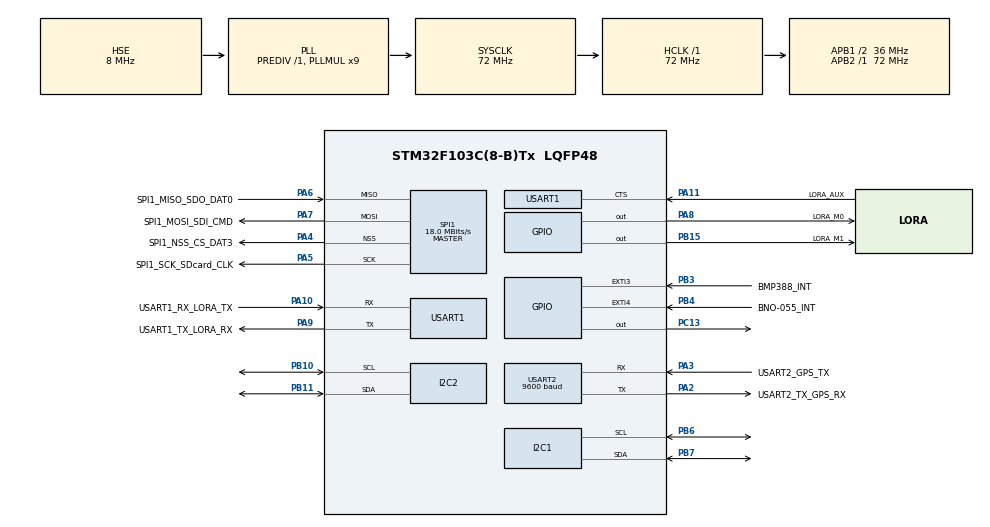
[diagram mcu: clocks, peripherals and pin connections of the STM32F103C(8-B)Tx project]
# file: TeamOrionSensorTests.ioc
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Dma.I2C1_RX.0.Direction=DMA_PERIPH_TO_MEMORY
Dma.I2C1_RX.0.Instance=DMA1_Channel7
Dma.I2C1_RX.0.MemDataAlignment=DMA_MDATAALIGN_BYTE
Dma.I2C1_RX.0.MemInc=DMA_MINC_ENABLE
Dma.I2C1_RX.0.Mode=DMA_NORMAL
Dma.I2C1_RX.0.PeriphDataAlignment=DMA_PDATAALIGN_BYTE
Dma.I2C1_RX.0.PeriphInc=DMA_PINC_DISABLE
Dma.I2C1_RX.0.Priority=DMA_PRIORITY_LOW
Dma.I2C1_TX.1.Direction=DMA_MEMORY_TO_PERIPH
Dma.I2C1_TX.1.Instance=DMA1_Channel6
Dma.I2C1_TX.1.MemDataAlignment=DMA_MDATAALIGN_BYTE
Dma.I2C1_TX.1.MemInc=DMA_MINC_ENABLE
Dma.I2C1_TX.1.Mode=DMA_NORMAL
Dma.I2C1_TX.1.PeriphDataAlignment=DMA_PDATAALIGN_BYTE
Dma.I2C1_TX.1.PeriphInc=DMA_PINC_DISABLE
Dma.I2C1_TX.1.Priority=DMA_PRIORITY_LOW
Dma.Request0=I2C1_RX
Dma.Request1=I2C1_TX
Dma.Request2=USART1_RX
Dma.Request3=USART1_TX
Dma.Request4=SPI1_RX
Dma.Request5=SPI1_TX
Dma.SPI1_RX.4.Direction=DMA_PERIPH_TO_MEMORY
Dma.SPI1_RX.4.Instance=DMA1_Channel2
Dma.SPI1_RX.4.MemDataAlignment=DMA_MDATAALIGN_BYTE
Dma.SPI1_RX.4.MemInc=DMA_MINC_ENABLE
Dma.SPI1_RX.4.Mode=DMA_NORMAL
Dma.SPI1_RX.4.PeriphDataAlignment=DMA_PDATAALIGN_BYTE
Dma.SPI1_RX.4.PeriphInc=DMA_PINC_DISABLE
Dma.SPI1_RX.4.Priority=DMA_PRIORITY_LOW
Dma.SPI1_TX.5.Direction=DMA_MEMORY_TO_PERIPH
Dma.SPI1_TX.5.Instance=DMA1_Channel3
Dma.SPI1_TX.5.MemDataAlignment=DMA_MDATAALIGN_BYTE
Dma.SPI1_TX.5.MemInc=DMA_MINC_ENABLE
Dma.SPI1_TX.5.Mode=DMA_NORMAL
Dma.SPI1_TX.5.PeriphDataAlignment=DMA_PDATAALIGN_BYTE
Dma.SPI1_TX.5.PeriphInc=DMA_PINC_DISABLE
Dma.SPI1_TX.5.Priority=DMA_PRIORITY_LOW
Dma.USART1_RX.2.Direction=DMA_PERIPH_TO_MEMORY
Dma.USART1_RX.2.Instance=DMA1_Channel5
Dma.USART1_RX.2.MemDataAlignment=DMA_MDATAALIGN_BYTE
Dma.USART1_RX.2.MemInc=DMA_MINC_ENABLE
Dma.USART1_RX.2.Mode=DMA_NORMAL
Dma.USART1_RX.2.PeriphDataAlignment=DMA_PDATAALIGN_BYTE
Dma.USART1_RX.2.PeriphInc=DMA_PINC_DISABLE
Dma.USART1_RX.2.Priority=DMA_PRIORITY_LOW
Dma.USART1_TX.3.Direction=DMA_MEMORY_TO_PERIPH
Dma.USART1_TX.3.Instance=DMA1_Channel4
Dma.USART1_TX.3.MemDataAlignment=DMA_MDATAALIGN_BYTE
Dma.USART1_TX.3.MemInc=DMA_MINC_ENABLE
Dma.USART1_TX.3.Mode=DMA_NORMAL
Dma.USART1_TX.3.PeriphDataAlignment=DMA_PDATAALIGN_BYTE
Dma.USART1_TX.3.PeriphInc=DMA_PINC_DISABLE
Dma.USART1_TX.3.Priority=DMA_PRIORITY_LOW
Mcu.Family=STM32F1
Mcu.Name=STM32F103C(8-B)Tx
Mcu.Package=LQFP48
NVIC.DMA1_Channel2_IRQn=true\:0\:0\:false\:false\:true\:false\:true\:true
NVIC.DMA1_Channel3_IRQn=true\:0\:0\:false\:false\:true\:false\:true\:true
NVIC.DMA1_Channel4_IRQn=true\:0\:0\:false\:false\:true\:false\:true\:true
NVIC.DMA1_Channel5_IRQn=true\:0\:0\:false\:false\:true\:false\:true\:true
NVIC.DMA1_Channel6_IRQn=true\:0\:0\:false\:false\:true\:false\:true\:true
NVIC.DMA1_Channel7_IRQn=true\:0\:0\:false\:false\:true\:false\:true\:true
NVIC.PriorityGroup=NVIC_PRIORITYGROUP_4
NVIC.USART2_IRQn=true\:0\:0\:false\:false\:true\:true\:true\:true
PA10.GPIO_Label=USART1_RX_LORA_TX
PA10.Mode=Asynchronous
PA10.Signal=USART1_RX
PA11.GPIO_Label=LORA_AUX
PA11.Mode=CTS_Only
PA11.Signal=USART1_CTS
PA13.Mode=Serial_Wire
PA13.Signal=SYS_JTMS-SWDIO
PA14.Mode=Serial_Wire
PA14.Signal=SYS_JTCK-SWCLK
PA2.GPIO_Label=USART2_TX_GPS_RX
PA2.Mode=Asynchronous
PA2.Signal=USART2_TX
PA3.GPIO_Label=USART2_GPS_TX
PA3.Mode=Asynchronous
PA3.Signal=USART2_RX
PA4.GPIO_Label=SPI1_NSS_CS_DAT3
PA4.Mode=NSS_Signal_Hard_Output
PA4.Signal=SPI1_NSS
PA5.GPIO_Label=SPI1_SCK_SDcard_CLK
PA5.Mode=Full_Duplex_Master
PA5.Signal=SPI1_SCK
PA6.GPIO_Label=SPI1_MISO_SDO_DAT0
PA6.Mode=Full_Duplex_Master
PA6.Signal=SPI1_MISO
PA7.GPIO_Label=SPI1_MOSI_SDI_CMD
PA7.Mode=Full_Duplex_Master
PA7.Signal=SPI1_MOSI
PA8.GPIO_Label=LORA_M0
PA8.Signal=GPIO_Output
PA9.GPIO_Label=USART1_TX_LORA_RX
PA9.Mode=Asynchronous
PA9.Signal=USART1_TX
PB10.Mode=I2C
PB10.Signal=I2C2_SCL
PB11.Mode=I2C
PB11.Signal=I2C2_SDA
PB15.GPIO_Label=LORA_M1
PB15.Signal=GPIO_Output
PB3.GPIO_Label=BMP388_INT
PB3.Signal=GPXTI3
PB4.GPIO_Label=BNO-055_INT
PB4.Signal=GPXTI4
PB6.Mode=I2C
PB6.Signal=I2C1_SCL
PB7.Mode=I2C
PB7.Signal=I2C1_SDA
PC13-TAMPER-RTC.GPIO_ModeDefaultOutputPP=GPIO_MODE_OUTPUT_PP
PC13-TAMPER-RTC.GPIO_Speed=GPIO_SPEED_FREQ_HIGH
PC13-TAMPER-RTC.Signal=GPIO_Output
PD0-OSC_IN.Mode=HSE-External-Oscillator
PD0-OSC_IN.Signal=RCC_OSC_IN
PD1-OSC_OUT.Mode=HSE-External-Oscillator
PD1-OSC_OUT.Signal=RCC_OSC_OUT
ProjectManager.HeapSize=0x200
ProjectManager.StackSize=0x400
ProjectManager.TargetToolchain=MDK-ARM V5.32
RCC.AHBFreq_Value=72000000
RCC.APB1CLKDivider=RCC_HCLK_DIV2
RCC.APB1Freq_Value=36000000
RCC.APB1TimFreq_Value=72000000
RCC.APB2Freq_Value=72000000
RCC.APB2TimFreq_Value=72000000
RCC.HCLKFreq_Value=72000000
RCC.PLLMUL=RCC_PLL_MUL9
RCC.PLLSourceVirtual=RCC_PLLSOURCE_HSE
RCC.SYSCLKFreq_VALUE=72000000
RCC.SYSCLKSource=RCC_SYSCLKSOURCE_PLLCLK
RCC.USBFreq_Value=72000000
SPI1.BaudRatePrescaler=SPI_BAUDRATEPRESCALER_4
SPI1.CLKPhase=SPI_PHASE_1EDGE
SPI1.CalculateBaudRate=18.0 MBits/s
SPI1.DataSize=SPI_DATASIZE_8BIT
SPI1.Direction=SPI_DIRECTION_2LINES
SPI1.Mode=SPI_MODE_MASTER
SPI1.VirtualNSS=VM_NSSHARD
SPI1.VirtualType=VM_MASTER
USART1.VirtualMode=VM_ASYNC
USART2.BaudRate=9600
USART2.VirtualMode=VM_ASYNC
board=custom

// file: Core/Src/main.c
/* USER CODE BEGIN Header */
/**
  ******************************************************************************
  * @file           : main.c
  * @brief          : Main program body
  ******************************************************************************
  * @attention
  *
  * Copyright (c) 2023 STMicroelectronics.
  * All rights reserved.
  *
  * This software is licensed under terms that can be found in the LICENSE file
  * in the root directory of this software component.
  * If no LICENSE file comes with this software, it is provided AS-IS.
  *
  ******************************************************************************
  */
/* USER CODE END Header */
#include "main.h"
#include "dma.h"
#include "i2c.h"
#include "spi.h"
#include "usart.h"
#include "gpio.h"

/* USER CODE BEGIN Includes */
#include "bno055_stm32.h"
#include "_BMP388.h"
#include "gps.h"
/* USER CODE END Includes */

/* USER CODE BEGIN PV */
//uint8_t x = 0;
//uint8_t y = 0;
//volatile double pressure = 0.0;
//volatile double temperature = 0.0;
//volatile double altitude = 0.0;
calibINTCoefficents calibINT;
//bno055_vector_t euler;
//bno055_vector_t quaternion;

float gpsAltitude;
float Latitude;
float Longitude;

GPS_t GPS;

/* USER CODE END PV */

void SystemClock_Config(void);

int main(void)
{

  /* MCU Configuration--------------------------------------------------------*/

  /* Reset of all peripherals, Initializes the Flash interface and the Systick. */
  HAL_Init();

  /* Configure the system clock */
  SystemClock_Config();

  /* Initialize all configured peripherals */
  MX_GPIO_Init();
  MX_DMA_Init();
  MX_I2C1_Init();
  MX_USART1_UART_Init();
  MX_SPI1_Init();
  MX_USART2_UART_Init();
  MX_I2C2_Init();
  /* USER CODE BEGIN 2 */

  GPS_Init();//GPS START COMMAND

//  bno055_setup();
//  bno055_setOperationMode(BNO055_OPERATION_MODE_NDOF);
//  x = BMP388_TestSensor();
//  y = BMP388_ReadID();
//  //															Pressure		Temperature
//  x = begin(NORMAL_MODE, IIR_FILTER_OFF, TIME_STANDBY_5MS, OVERSAMPLING_SKIP, OVERSAMPLING_SKIP);
//  readCoef();
  /* USER CODE END 2 */

  /* Infinite loop */
  while (1)
  {

    /* USER CODE BEGIN 3 */
//	euler = bno055_getVector(BNO055_VECTOR_EULER);
//	//printf("Heading: %.2f Roll: %.2f Pitch: %.2f\r\n", euler.x, euler.y, euler.z);
//	quaternion = bno055_getVector(BNO055_VECTOR_QUATERNION);
//	//printf("W: %.2f X: %.2f Y: %.2f Z: %.2f\r\n", quaternion.w, quaternion.x, quaternion.y, quaternion.z);
//	//HAL_Delay(10);
//	y = getBMP_Data(&temperature, &pressure, &altitude);

	  HAL_GPIO_TogglePin(GPIOC,13);
 	  gpsAltitude = GPS.msl_altitude;
	  Latitude = GPS.dec_latitude;
	  Longitude = GPS.dec_longitude;
	  HAL_GPIO_TogglePin(GPIOC, 13);

  }
  /* USER CODE END 3 */
}

void SystemClock_Config(void)
{
  RCC_OscInitTypeDef RCC_OscInitStruct = {0};
  RCC_ClkInitTypeDef RCC_ClkInitStruct = {0};

  /** Initializes the RCC Oscillators according to the specified parameters
  * in the RCC_OscInitTypeDef structure.
  */
  RCC_OscInitStruct.OscillatorType = RCC_OSCILLATORTYPE_HSE;
  RCC_OscInitStruct.HSEState = RCC_HSE_ON;
  RCC_OscInitStruct.HSEPredivValue = RCC_HSE_PREDIV_DIV1;
  RCC_OscInitStruct.HSIState = RCC_HSI_ON;
  RCC_OscInitStruct.PLL.PLLState = RCC_PLL_ON;
  RCC_OscInitStruct.PLL.PLLSource = RCC_PLLSOURCE_HSE;
  RCC_OscInitStruct.PLL.PLLMUL = RCC_PLL_MUL9;
  if (HAL_RCC_OscConfig(&RCC_OscInitStruct) != HAL_OK)
  {
    Error_Handler();
  }

  /** Initializes the CPU, AHB and APB buses clocks
  */
  RCC_ClkInitStruct.ClockType = RCC_CLOCKTYPE_HCLK|RCC_CLOCKTYPE_SYSCLK
                              |RCC_CLOCKTYPE_PCLK1|RCC_CLOCKTYPE_PCLK2;
  RCC_ClkInitStruct.SYSCLKSource = RCC_SYSCLKSOURCE_PLLCLK;
  RCC_ClkInitStruct.AHBCLKDivider = RCC_SYSCLK_DIV1;
  RCC_ClkInitStruct.APB1CLKDivider = RCC_HCLK_DIV2;
  RCC_ClkInitStruct.APB2CLKDivider = RCC_HCLK_DIV1;

  if (HAL_RCC_ClockConfig(&RCC_ClkInitStruct, FLASH_LATENCY_2) != HAL_OK)
  {
    Error_Handler();
  }
}

void Error_Handler(void)
{
  __disable_irq();
  while (1)
  {
  }
}
